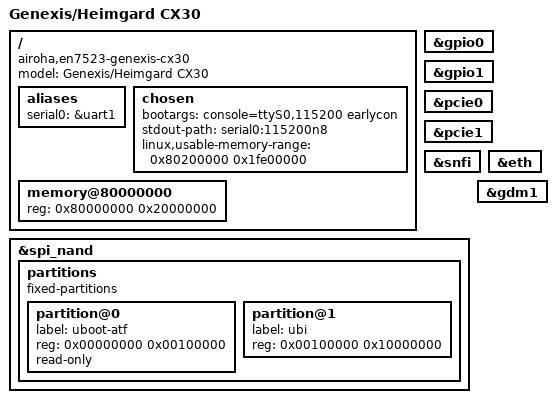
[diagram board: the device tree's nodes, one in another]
// SPDX-License-Identifier: (GPL-2.0-only OR BSD-2-Clause)
/dts-v1/;

/* Bootloader installs ATF here */
/memreserve/ 0x80000000 0x200000;

#include <dt-bindings/input/linux-event-codes.h>
#include <dt-bindings/gpio/gpio.h>
#include "en7523.dtsi"

/ {
	model = "Genexis/Heimgard CX30";
	compatible = "airoha,en7523-genexis-cx30", "airoha,en7523";

	aliases {
		serial0 = &uart1;
	};

	chosen {
		bootargs = "console=ttyS0,115200 earlycon";
		stdout-path = "serial0:115200n8";
		linux,usable-memory-range = <0x80200000 0x1fe00000>;
	};

	memory@80000000 {
		device_type = "memory";
		reg = <0x80000000 0x20000000>;
	};
};

&gpio0 {
	status = "okay";
};

&gpio1 {
	status = "okay";
};

&pcie0 {
	status = "okay";
};

&pcie1 {
	status = "okay";
};

&snfi {
	status = "okay";
};

&spi_nand {
	partitions {
		compatible = "fixed-partitions";
		#address-cells = <1>;
		#size-cells = <1>;

		partition@0 {
			label = "uboot-atf";
			reg = <0x00000000 0x00100000>;
			read-only;
		};

		partition@1 {
			label = "ubi";
			reg = <0x00100000 0x10000000>;
		};
	};
};

&eth {
	status = "okay";
};

&gdm1 {
	status = "okay";
};
